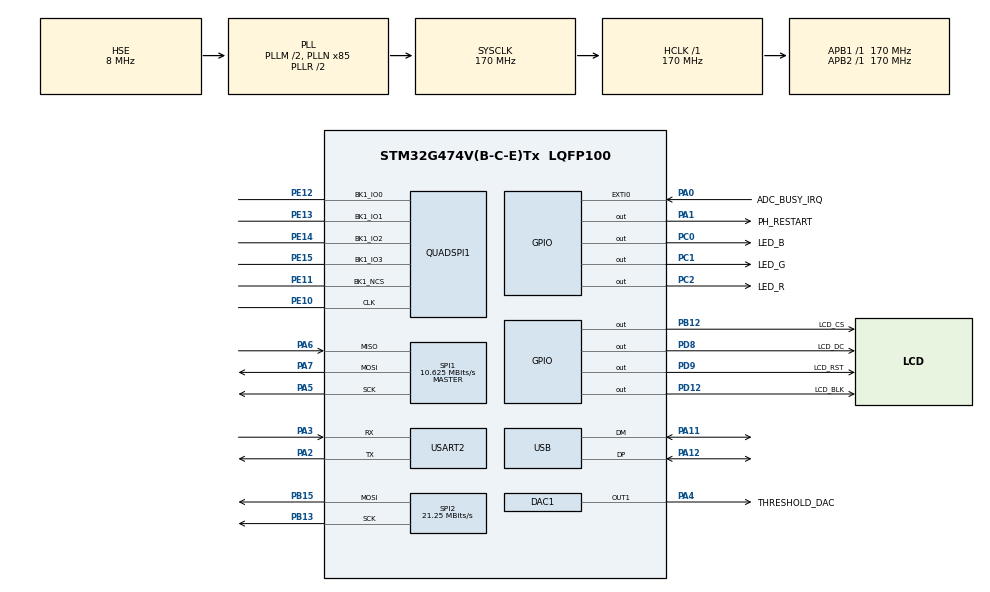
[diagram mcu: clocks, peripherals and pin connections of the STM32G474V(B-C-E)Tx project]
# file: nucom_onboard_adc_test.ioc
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ADC1.Channel-0\#ChannelRegularConversion=ADC_CHANNEL_9
ADC1.ClockPrescaler=ADC_CLOCK_SYNC_PCLK_DIV4
ADC1.ContinuousConvMode=DISABLE
ADC1.DMAContinuousRequests=DISABLE
ADC1.DataAlign=ADC_DATAALIGN_RIGHT
ADC1.DiscontinuousConvMode=DISABLE
ADC1.EOCSelection=ADC_EOC_SINGLE_CONV
ADC1.EnableAnalogWatchDog1=false
ADC1.EnableAnalogWatchDog2=false
ADC1.EnableAnalogWatchDog3=false
ADC1.EnableInjectedConversion=DISABLE
ADC1.EnableRegularConversion=ENABLE
ADC1.ExternalTrigConv=ADC_EXTERNALTRIG_T7_TRGO
ADC1.ExternalTrigConvEdge=ADC_EXTERNALTRIGCONVEDGE_RISING
ADC1.LowPowerAutoWait=DISABLE
ADC1.Mode=ADC_MODE_INDEPENDENT
ADC1.NbrOfConversion=1
ADC1.OffsetNumber-0\#ChannelRegularConversion=ADC_OFFSET_NONE
ADC1.Overrun=ADC_OVR_DATA_OVERWRITTEN
ADC1.OversamplingMode=DISABLE
ADC1.Rank-0\#ChannelRegularConversion=1
ADC1.Resolution=ADC_RESOLUTION_12B
ADC1.SamplingTime-0\#ChannelRegularConversion=ADC_SAMPLETIME_6CYCLES_5
ADC1.ScanConvMode=ADC_SCAN_DISABLE
ADC1.master=1
DAC1.DAC_Trigger_OUT1-DAC_OUT1=DAC_TRIGGER_T6_TRGO
Dma.Request0=SPI1_RX
Dma.Request1=SPI1_TX
Dma.Request2=SPI2_TX
Dma.Request3=ADC1
Dma.Request4=DAC1_CH1
Dma.ADC1.3.Direction=DMA_PERIPH_TO_MEMORY
Dma.ADC1.3.EventEnable=DISABLE
Dma.ADC1.3.Instance=DMA1_Channel4
Dma.ADC1.3.MemDataAlignment=DMA_MDATAALIGN_HALFWORD
Dma.ADC1.3.MemInc=DMA_MINC_ENABLE
Dma.ADC1.3.Mode=DMA_NORMAL
Dma.ADC1.3.PeriphDataAlignment=DMA_PDATAALIGN_HALFWORD
Dma.ADC1.3.PeriphInc=DMA_PINC_DISABLE
Dma.ADC1.3.Polarity=HAL_DMAMUX_REQ_GEN_RISING
Dma.ADC1.3.Priority=DMA_PRIORITY_VERY_HIGH
Dma.ADC1.3.RequestNumber=1
Dma.ADC1.3.SignalID=NONE
Dma.ADC1.3.SyncEnable=DISABLE
Dma.ADC1.3.SyncPolarity=HAL_DMAMUX_SYNC_NO_EVENT
Dma.ADC1.3.SyncRequestNumber=1
Dma.ADC1.3.SyncSignalID=NONE
Dma.DAC1_CH1.4.Direction=DMA_MEMORY_TO_PERIPH
Dma.DAC1_CH1.4.EventEnable=DISABLE
Dma.DAC1_CH1.4.Instance=DMA1_Channel5
Dma.DAC1_CH1.4.MemDataAlignment=DMA_MDATAALIGN_HALFWORD
Dma.DAC1_CH1.4.MemInc=DMA_MINC_ENABLE
Dma.DAC1_CH1.4.Mode=DMA_CIRCULAR
Dma.DAC1_CH1.4.PeriphDataAlignment=DMA_PDATAALIGN_WORD
Dma.DAC1_CH1.4.PeriphInc=DMA_PINC_DISABLE
Dma.DAC1_CH1.4.Polarity=HAL_DMAMUX_REQ_GEN_RISING
Dma.DAC1_CH1.4.Priority=DMA_PRIORITY_HIGH
Dma.DAC1_CH1.4.RequestNumber=1
Dma.DAC1_CH1.4.SignalID=NONE
Dma.DAC1_CH1.4.SyncEnable=DISABLE
Dma.DAC1_CH1.4.SyncPolarity=HAL_DMAMUX_SYNC_NO_EVENT
Dma.DAC1_CH1.4.SyncRequestNumber=1
Dma.DAC1_CH1.4.SyncSignalID=NONE
Dma.SPI1_RX.0.Direction=DMA_PERIPH_TO_MEMORY
Dma.SPI1_RX.0.EventEnable=DISABLE
Dma.SPI1_RX.0.Instance=DMA1_Channel1
Dma.SPI1_RX.0.MemDataAlignment=DMA_MDATAALIGN_HALFWORD
Dma.SPI1_RX.0.MemInc=DMA_MINC_ENABLE
Dma.SPI1_RX.0.Mode=DMA_NORMAL
Dma.SPI1_RX.0.PeriphDataAlignment=DMA_PDATAALIGN_HALFWORD
Dma.SPI1_RX.0.PeriphInc=DMA_PINC_DISABLE
Dma.SPI1_RX.0.Polarity=HAL_DMAMUX_REQ_GEN_RISING
Dma.SPI1_RX.0.Priority=DMA_PRIORITY_VERY_HIGH
Dma.SPI1_RX.0.RequestNumber=1
Dma.SPI1_RX.0.SignalID=NONE
Dma.SPI1_RX.0.SyncEnable=DISABLE
Dma.SPI1_RX.0.SyncPolarity=HAL_DMAMUX_SYNC_NO_EVENT
Dma.SPI1_RX.0.SyncRequestNumber=1
Dma.SPI1_RX.0.SyncSignalID=NONE
Dma.SPI1_TX.1.Direction=DMA_MEMORY_TO_PERIPH
Dma.SPI1_TX.1.EventEnable=DISABLE
Dma.SPI1_TX.1.Instance=DMA1_Channel2
Dma.SPI1_TX.1.MemDataAlignment=DMA_MDATAALIGN_HALFWORD
Dma.SPI1_TX.1.MemInc=DMA_MINC_DISABLE
Dma.SPI1_TX.1.Mode=DMA_NORMAL
Dma.SPI1_TX.1.PeriphDataAlignment=DMA_PDATAALIGN_HALFWORD
Dma.SPI1_TX.1.PeriphInc=DMA_PINC_DISABLE
Dma.SPI1_TX.1.Polarity=HAL_DMAMUX_REQ_GEN_RISING
Dma.SPI1_TX.1.Priority=DMA_PRIORITY_HIGH
Dma.SPI1_TX.1.RequestNumber=1
Dma.SPI1_TX.1.SignalID=NONE
Dma.SPI1_TX.1.SyncEnable=DISABLE
Dma.SPI1_TX.1.SyncPolarity=HAL_DMAMUX_SYNC_NO_EVENT
Dma.SPI1_TX.1.SyncRequestNumber=1
Dma.SPI1_TX.1.SyncSignalID=NONE
Dma.SPI2_TX.2.Direction=DMA_MEMORY_TO_PERIPH
Dma.SPI2_TX.2.EventEnable=DISABLE
Dma.SPI2_TX.2.Instance=DMA1_Channel3
Dma.SPI2_TX.2.MemDataAlignment=DMA_MDATAALIGN_BYTE
Dma.SPI2_TX.2.MemInc=DMA_MINC_ENABLE
Dma.SPI2_TX.2.Mode=DMA_NORMAL
Dma.SPI2_TX.2.PeriphDataAlignment=DMA_PDATAALIGN_BYTE
Dma.SPI2_TX.2.PeriphInc=DMA_PINC_DISABLE
Dma.SPI2_TX.2.Polarity=HAL_DMAMUX_REQ_GEN_RISING
Dma.SPI2_TX.2.Priority=DMA_PRIORITY_LOW
Dma.SPI2_TX.2.RequestNumber=1
Dma.SPI2_TX.2.SignalID=NONE
Dma.SPI2_TX.2.SyncEnable=DISABLE
Dma.SPI2_TX.2.SyncPolarity=HAL_DMAMUX_SYNC_NO_EVENT
Dma.SPI2_TX.2.SyncRequestNumber=1
Dma.SPI2_TX.2.SyncSignalID=NONE
Mcu.Family=STM32G4
Mcu.Name=STM32G474V(B-C-E)Tx
Mcu.Package=LQFP100
NVIC.DMA1_Channel1_IRQn=true\:2\:0\:true\:false\:true\:false\:true\:true
NVIC.DMA1_Channel2_IRQn=true\:2\:0\:true\:false\:true\:false\:true\:true
NVIC.DMA1_Channel3_IRQn=true\:6\:0\:true\:false\:true\:false\:true\:true
NVIC.DMA1_Channel4_IRQn=true\:3\:0\:true\:false\:true\:false\:true\:true
NVIC.DMA1_Channel5_IRQn=true\:4\:0\:true\:false\:true\:false\:true\:true
NVIC.EXTI0_IRQn=true\:1\:0\:true\:false\:true\:true\:true\:true
NVIC.PriorityGroup=NVIC_PRIORITYGROUP_4
NVIC.SPI1_IRQn=true\:2\:0\:true\:false\:true\:true\:true\:true
NVIC.SPI2_IRQn=true\:6\:0\:true\:false\:true\:true\:true\:true
NVIC.USB_LP_IRQn=true\:5\:0\:true\:false\:true\:false\:true\:true
PA0.GPIO_Label=ADC_BUSY_IRQ
PA0.GPIO_ModeDefaultEXTI=GPIO_MODE_IT_FALLING
PA0.Signal=GPXTI0
PA1.GPIO_Label=PH_RESTART
PA1.GPIO_PuPd=GPIO_NOPULL
PA1.Signal=GPIO_Output
PA13.Mode=Serial_Wire
PA13.Signal=SYS_JTMS-SWDIO
PA14.Mode=Serial_Wire
PA14.Signal=SYS_JTCK-SWCLK
PA2.Mode=Asynchronous
PA2.Signal=USART2_TX
PA3.Mode=Asynchronous
PA3.Signal=USART2_RX
PA4.GPIO_Label=THRESHOLD_DAC
PA4.Signal=COMP_DAC11_group
PA5.Mode=Full_Duplex_Master
PA5.GPIO_Speed=GPIO_SPEED_FREQ_HIGH
PA5.Signal=SPI1_SCK
PA6.Mode=Full_Duplex_Master
PA6.GPIO_Speed=GPIO_SPEED_FREQ_HIGH
PA6.Signal=SPI1_MISO
PA7.Mode=Full_Duplex_Master
PA7.GPIO_Speed=GPIO_SPEED_FREQ_HIGH
PA7.Signal=SPI1_MOSI
PA11.Mode=Device
PA11.Signal=USB_DM
PA12.Mode=Device
PA12.Signal=USB_DP
PB12.GPIO_Label=LCD_CS
PB12.PinState=GPIO_PIN_SET
PB12.Signal=GPIO_Output
PB13.Mode=TX_Only_Simplex_Unidirect_Master
PB13.GPIO_Speed=GPIO_SPEED_FREQ_VERY_HIGH
PB13.Signal=SPI2_SCK
PB15.Mode=TX_Only_Simplex_Unidirect_Master
PB15.GPIO_Speed=GPIO_SPEED_FREQ_VERY_HIGH
PB15.Signal=SPI2_MOSI
PC0.GPIO_Label=LED_B
PC0.PinState=GPIO_PIN_SET
PC0.Signal=GPIO_Output
PC1.GPIO_Label=LED_G
PC1.PinState=GPIO_PIN_SET
PC1.Signal=GPIO_Output
PC2.GPIO_Label=LED_R
PC2.PinState=GPIO_PIN_SET
PC2.Signal=GPIO_Output
PC3.Signal=ADC1_IN9
PD12.GPIO_Label=LCD_BLK
PD12.PinState=GPIO_PIN_SET
PD12.Signal=GPIO_Output
PD8.GPIO_Label=LCD_DC
PD8.Signal=GPIO_Output
PD9.GPIO_Label=LCD_RST
PD9.Signal=GPIO_Output
PE10.Mode=Single Bank 1
PE10.GPIO_Speed=GPIO_SPEED_FREQ_VERY_HIGH
PE10.Signal=QUADSPI1_CLK
PE11.Mode=Single Bank 1
PE11.GPIO_Speed=GPIO_SPEED_FREQ_VERY_HIGH
PE11.Signal=QUADSPI1_BK1_NCS
PE12.Mode=Single Bank 1
PE12.GPIO_Speed=GPIO_SPEED_FREQ_VERY_HIGH
PE12.Signal=QUADSPI1_BK1_IO0
PE13.Mode=Single Bank 1
PE13.GPIO_Speed=GPIO_SPEED_FREQ_VERY_HIGH
PE13.Signal=QUADSPI1_BK1_IO1
PE14.Mode=Single Bank 1
PE14.GPIO_Speed=GPIO_SPEED_FREQ_VERY_HIGH
PE14.Signal=QUADSPI1_BK1_IO2
PE15.Mode=Single Bank 1
PE15.GPIO_Speed=GPIO_SPEED_FREQ_VERY_HIGH
PE15.Signal=QUADSPI1_BK1_IO3
PF0-OSC_IN.Mode=HSE-External-Oscillator
PF0-OSC_IN.Signal=RCC_OSC_IN
PF1-OSC_OUT.Mode=HSE-External-Oscillator
PF1-OSC_OUT.Signal=RCC_OSC_OUT
ProjectManager.HeapSize=0x200
ProjectManager.StackSize=0x400
ProjectManager.TargetToolchain=STM32CubeIDE
QUADSPI1.ChipSelectHighTime=QSPI_CS_HIGH_TIME_3_CYCLE
QUADSPI1.ClockPrescaler=3
QUADSPI1.FifoThreshold=4
QUADSPI1.FlashSize=21
QUADSPI1.SampleShifting=QSPI_SAMPLE_SHIFTING_HALFCYCLE
RCC.ADC12Freq_Value=170000000
RCC.ADC345Freq_Value=170000000
RCC.AHBFreq_Value=170000000
RCC.APB1Freq_Value=170000000
RCC.APB1TimFreq_Value=170000000
RCC.APB2Freq_Value=170000000
RCC.APB2TimFreq_Value=170000000
RCC.CortexFreq_Value=170000000
RCC.EXTERNAL_CLOCK_VALUE=12288000
RCC.HCLKFreq_Value=170000000
RCC.HSE_VALUE=8000000
RCC.HSI48_VALUE=48000000
RCC.HSI_VALUE=16000000
RCC.LSE_VALUE=32768
RCC.PLLM=RCC_PLLM_DIV2
RCC.PLLN=85
RCC.PLLSourceVirtual=RCC_PLLSOURCE_HSE
RCC.SYSCLKFreq_VALUE=170000000
RCC.SYSCLKSource=RCC_SYSCLKSOURCE_PLLCLK
RCC.USBFreq_Value=48000000
RCC.VCOOutputFreq_Value=340000000
SH.COMP_DAC11_group.0=DAC1_OUT1,DAC_OUT1
SPI1.BaudRatePrescaler=SPI_BAUDRATEPRESCALER_16
SPI1.CLKPhase=SPI_PHASE_2EDGE
SPI1.CLKPolarity=SPI_POLARITY_HIGH
SPI1.CalculateBaudRate=10.625 MBits/s
SPI1.DataSize=SPI_DATASIZE_16BIT
SPI1.Direction=SPI_DIRECTION_2LINES
SPI1.Mode=SPI_MODE_MASTER
SPI1.VirtualType=VM_MASTER
SPI2.BaudRatePrescaler=SPI_BAUDRATEPRESCALER_8
SPI2.CalculateBaudRate=21.25 MBits/s
SPI2.DataSize=SPI_DATASIZE_8BIT
SPI2.Direction=SPI_DIRECTION_2LINES
SPI2.Mode=SPI_MODE_MASTER
SPI2.VirtualType=VM_MASTER
TIM6.AutoReloadPreload=TIM_AUTORELOAD_PRELOAD_DISABLE
TIM6.CounterMode=TIM_COUNTERMODE_UP
TIM6.Dithering=Disable
TIM6.PeriodNoDither=169
TIM6.Prescaler=0
TIM6.TIM_MasterOutputTrigger=TIM_TRGO_UPDATE
TIM7.AutoReloadPreload=TIM_AUTORELOAD_PRELOAD_DISABLE
TIM7.CounterMode=TIM_COUNTERMODE_UP
TIM7.Dithering=Disable
TIM7.PeriodNoDither=84
TIM7.Prescaler=0
TIM7.TIM_MasterOutputTrigger=TIM_TRGO_UPDATE
USART2.VirtualMode-Asynchronous=VM_ASYNC
USB.DeviceSpeed=PCD_SPEED_FULL
USB.Sof_enable=DISABLE
USB.battery_charging_enable=DISABLE
USB.low_power_enable=DISABLE
USB.lpm_enable=DISABLE
USB.phy_itface=PCD_PHY_EMBEDDED
USB_DEVICE.APP_RX_DATA_SIZE=512
USB_DEVICE.APP_TX_DATA_SIZE=512
USB_DEVICE.CLASS_NAME_FS=CDC
USB_DEVICE.CONFIGURATION_STRING_CDC_FS=NUCOM DAQ CDC
USB_DEVICE.INTERFACE_STRING_CDC_FS=DAQ Command Port
USB_DEVICE.LANGID_STRING=1033
USB_DEVICE.MANUFACTURER_STRING=NUCOM Team
USB_DEVICE.PID_CDC_FS=0x5740
USB_DEVICE.PRODUCT_STRING_CDC_FS=NUCOM G474 DAQ
USB_DEVICE.USBD_DEBUG_LEVEL=0
USB_DEVICE.USBD_LPM_ENABLED=0
USB_DEVICE.USBD_MAX_NUM_CONFIGURATION=1
USB_DEVICE.USBD_MAX_NUM_INTERFACES=1
USB_DEVICE.USBD_MAX_STR_DESC_SIZ=100
USB_DEVICE.USBD_SELF_POWERED=1
USB_DEVICE.VID=0x483
USB_DEVICE.VirtualMode=Cdc
USB_DEVICE.VirtualModeFS=Cdc_FS
VP_USB_DEVICE_VS_USB_DEVICE_CDC_FS.Mode=CDC_FS
VP_SYS_VS_DBSignals.Mode=DisableDeadBatterySignals
VP_TIM6_VS_ClockSourceINT.Mode=Enable_Timer
VP_TIM7_VS_ClockSourceINT.Mode=Enable_Timer
board=custom

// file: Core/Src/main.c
/* USER CODE BEGIN Header */
/**
  ******************************************************************************
  * @file           : main.c
  * @brief          : Main program body
  ******************************************************************************
  * @attention
  *
  * Copyright (c) 2026 STMicroelectronics.
  * All rights reserved.
  *
  * This software is licensed under terms that can be found in the LICENSE file
  * in the root directory of this software component.
  * If no LICENSE file comes with this software, it is provided AS-IS.
  *
  ******************************************************************************
  */
/* USER CODE END Header */
#include "main.h"
#include "adc.h"
#include "dac.h"
#include "dma.h"
#include "quadspi.h"
#include "spi.h"
#include "usart.h"
#include "gpio.h"
#include "tim.h"

/* USER CODE BEGIN Includes */
#include "app.h"
#include "usb_device.h"
/* USER CODE END Includes */

void SystemClock_Config(void);

int main(void)
{

  /* MCU Configuration--------------------------------------------------------*/

  /* Reset of all peripherals, Initializes the Flash interface and the Systick. */
  HAL_Init();

  /* Configure the system clock */
  SystemClock_Config();

  /* Initialize all configured peripherals */
  MX_GPIO_Init();
  MX_DMA_Init();
  MX_TIM6_Init();
  MX_TIM7_Init();
  MX_ADC1_Init();
  MX_DAC1_Init();
  MX_SPI1_Init();
  MX_SPI2_Init();
  MX_QUADSPI1_Init();
  MX_USART2_UART_Init();
  /* USER CODE BEGIN 2 */
  MX_USB_Device_Init();
  App_Init();
  /* USER CODE END 2 */

  /* Infinite loop */
  while (1)
  {

    /* USER CODE BEGIN 3 */
    App_Task();
  }
  /* USER CODE END 3 */
}

void SystemClock_Config(void)
{
  RCC_OscInitTypeDef RCC_OscInitStruct = {0};
  RCC_ClkInitTypeDef RCC_ClkInitStruct = {0};

  /** Configure the main internal regulator output voltage
  */
  HAL_PWREx_ControlVoltageScaling(PWR_REGULATOR_VOLTAGE_SCALE1_BOOST);

  /** Initializes the RCC Oscillators according to the specified parameters
  * in the RCC_OscInitTypeDef structure.
  */
  RCC_OscInitStruct.OscillatorType = RCC_OSCILLATORTYPE_HSE;
  RCC_OscInitStruct.HSEState = RCC_HSE_ON;
  RCC_OscInitStruct.PLL.PLLState = RCC_PLL_ON;
  RCC_OscInitStruct.PLL.PLLSource = RCC_PLLSOURCE_HSE;
  RCC_OscInitStruct.PLL.PLLM = RCC_PLLM_DIV2;
  RCC_OscInitStruct.PLL.PLLN = 85;
  RCC_OscInitStruct.PLL.PLLP = RCC_PLLP_DIV2;
  RCC_OscInitStruct.PLL.PLLQ = RCC_PLLQ_DIV2;
  RCC_OscInitStruct.PLL.PLLR = RCC_PLLR_DIV2;
  if (HAL_RCC_OscConfig(&RCC_OscInitStruct) != HAL_OK)
  {
    Error_Handler();
  }

  /** Initializes the CPU, AHB and APB buses clocks
  */
  RCC_ClkInitStruct.ClockType = RCC_CLOCKTYPE_HCLK|RCC_CLOCKTYPE_SYSCLK
                              |RCC_CLOCKTYPE_PCLK1|RCC_CLOCKTYPE_PCLK2;
  RCC_ClkInitStruct.SYSCLKSource = RCC_SYSCLKSOURCE_PLLCLK;
  RCC_ClkInitStruct.AHBCLKDivider = RCC_SYSCLK_DIV1;
  RCC_ClkInitStruct.APB1CLKDivider = RCC_HCLK_DIV1;
  RCC_ClkInitStruct.APB2CLKDivider = RCC_HCLK_DIV1;

  if (HAL_RCC_ClockConfig(&RCC_ClkInitStruct, FLASH_LATENCY_4) != HAL_OK)
  {
    Error_Handler();
  }
}

void Error_Handler(void)
{
  __disable_irq();
  while (1)
  {
  }
}
